# J7AEP_GPU_BXS464_WRAP0_GPU_SS_0_CORE_MMRS register map
Vendor: Texas Instruments
Registers are 64-bit, access per field, reset 0x0 unless marked. A register's access mark holds for its fields unless they carry their own. Offsets are as the file gives them; [hi:lo] are bit positions; lines under a group give offsets from that group; {n}, {i} and the like mark numbered series; 'fields as' and 'values as' point back to an identical list.

## J7AEP_GPU_BXS464_WRAP0_GPU_SS_0_CORE_MMRS (part 2 of 4)
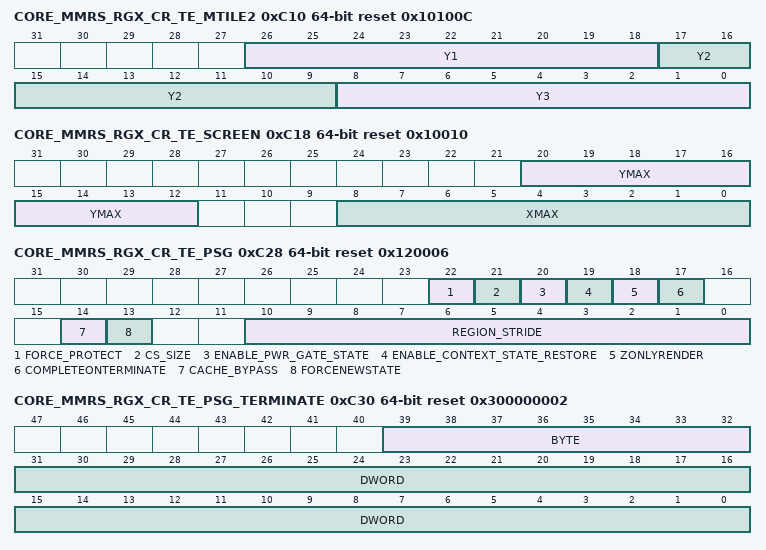
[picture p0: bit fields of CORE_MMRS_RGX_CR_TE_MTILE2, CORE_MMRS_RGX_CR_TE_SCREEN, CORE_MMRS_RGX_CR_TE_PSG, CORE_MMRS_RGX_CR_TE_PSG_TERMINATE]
0xC10 CORE_MMRS_RGX_CR_TE_MTILE2 reset 0x10100C
  [26:18] Y1 rw — X1 MacroTile boundary, ltop tile Y for second column of macrotiles [16MT mode] - 32 pixels tile height
  [17:9] Y2 rw — X2 MacroTile boundary, top tile Y for third[16MT] column of macrotiles - 32 pixels tile height
  [8:0] Y3 rw — X3 MacroTile boundary, top tile Y for fourth column of macrotiles [16MT] - 32 pixels tile height
0xC18 CORE_MMRS_RGX_CR_TE_SCREEN reset 0x10010
  [20:12] YMAX rw — Maximum Y tile address visible on screen, 32 pixel tile height, 16Kx16K max screen size
  [8:0] XMAX rw — Maximum X tile address visible on screen, 32 pixel tile width, 16Kx16K max screen size
0xC20 CORE_MMRS_RGX_CR_TE_MTILE
  [18:0] STRIDE rw — Number of tiles in a Macrotile. Stride = [XTile * YTiles], tiles 32 pixels across by 32 pixels
0xC28 CORE_MMRS_RGX_CR_TE_PSG reset 0x120006
  [22] FORCE_PROTECT rw — When set, the TE shall force the PROTECT bit to 1 for all tiles
  [21] CS_SIZE rw — Size of control stream chunk. 0x0 512 bit 0x1 1024 bit
  [20] ENABLE_PWR_GATE_STATE rw — Enables TE PSG power gate state init. 0x0 Disable 0x1 Enable
  [19] ENABLE_CONTEXT_STATE_RESTORE rw — Enables sampling of Driver TE_STATE_ISP_STATE_ID and TE_ACTIVE_MTILE registers on context switch/restore when set, when reset current local value is preserved.
  [18] ZONLYRENDER rw — Don't invalidate Tail Pointer Cache entries on a Terminate command. Only effective when COMPLETEONTERMINATE is 0x0 0x0 Do Invalidate 0x1 Don't Invalidate
  [17] COMPLETEONTERMINATE rw — 0x1 Write region headers, terminate streams and invalidate tail pointer cache entries on terminate. 0x0 If ZONLYRENDER = 0x0 then force an Interrupt, however if ZONLYRENDER = 0x1 then write region headers and terminate streams.
  [14] CACHE_BYPASS rw — when set, PSG sets its write only cache to bypass mode, effectively disabling the cache
  [13] FORCENEWSTATE rw — Always embed state information in control stream. Debug only.
  [10:0] REGION_STRIDE rw — Number of 4kB Pages devoted to region headers for each Render Target - max needed = 0x500
0xC30 CORE_MMRS_RGX_CR_TE_PSG_TERMINATE reset 0x300000002
  [39:32] BYTE rw — Byte to terminate all tile control streams with.
  [31:0] DWORD rw — Double-word to terminate all tile control streams with.
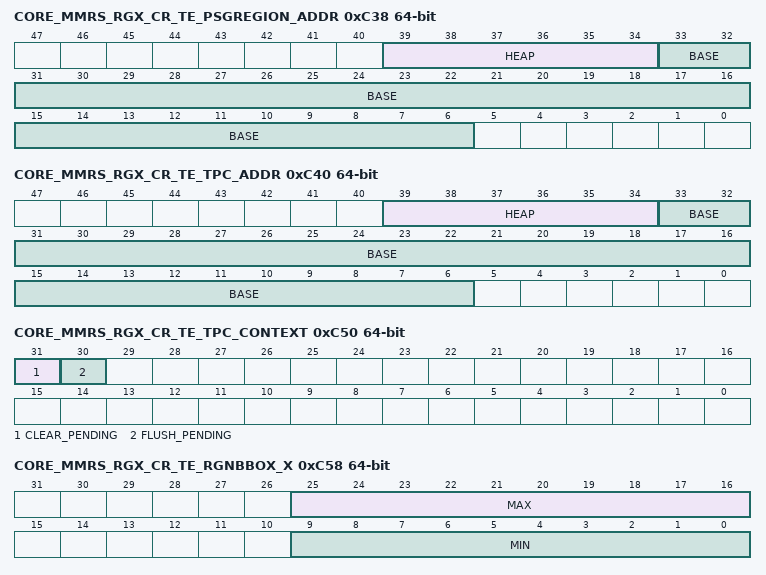
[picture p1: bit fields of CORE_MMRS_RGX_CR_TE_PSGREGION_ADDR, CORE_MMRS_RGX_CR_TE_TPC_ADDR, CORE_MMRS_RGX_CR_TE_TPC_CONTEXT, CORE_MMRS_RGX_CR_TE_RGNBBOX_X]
0xC38 CORE_MMRS_RGX_CR_TE_PSGREGION_ADDR
  [39:34] HEAP rw — 1TB Addressable, 16GB aligned Heap Address for Region Header writes
  [33:6] BASE rw — 16GB Addressable, 512-bit aligned Base Address for Region Header writes
0xC40 CORE_MMRS_RGX_CR_TE_TPC_ADDR
  [39:34] HEAP rw — 1TB Addressable, 16GB aligned Heap Address for Tail Pointer Cache.
  [33:6] BASE rw — 16GB Addressable, 512-bit aligned Base Address for Tail Pointer Cache entries. The tail pointer is the current last address written to for a control stream for a tile.
0xC48 CORE_MMRS_RGX_CR_TE_TPC reset 0x8
  [11:0] STRIDE rw — Number of 4KB pages per Render Target in each TPC footprint - max = 2048
0xC50 CORE_MMRS_RGX_CR_TE_TPC_CONTEXT
  [31] CLEAR_PENDING wo — Reset contents of Tail Pointer Cache
  [30] FLUSH_PENDING wo — Flush contents of Tail Pointer Cache to Memory
0xC58 CORE_MMRS_RGX_CR_TE_RGNBBOX_X ro
  [25:16] MAX — XMax value for maintained Region Generator Bounding Box, tiles 32 pixels in width
  [9:0] MIN — XMin value for maintained Region Generator Bounding Box, tiles 32 pixels in width
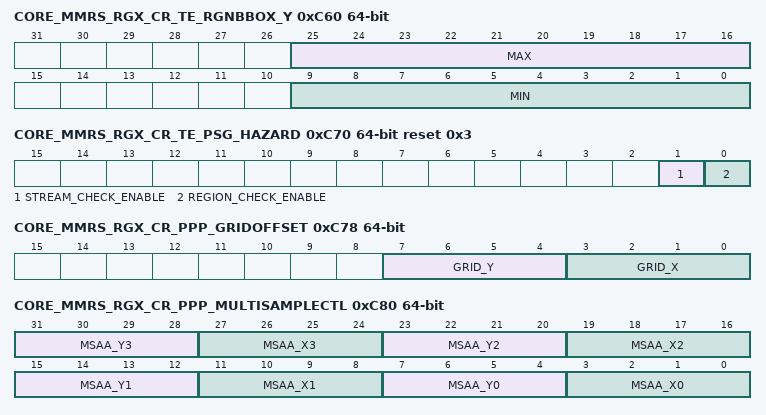
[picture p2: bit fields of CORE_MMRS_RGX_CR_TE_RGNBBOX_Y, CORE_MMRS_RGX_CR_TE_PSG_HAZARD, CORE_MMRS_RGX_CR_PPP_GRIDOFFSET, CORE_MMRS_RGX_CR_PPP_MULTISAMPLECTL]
0xC60 CORE_MMRS_RGX_CR_TE_RGNBBOX_Y ro
  [25:16] MAX — YMax value for maintained Region Generator Bounding Box, tiles 16 pixels in height
  [9:0] MIN — YMin value for maintained Region Generator Bounding Box, tiles 16 pixels in height
0xC68 CORE_MMRS_RGX_CR_TE_RGNHDR_INIT
  [0] PENDING wo — Start TE Region Header Initialisation
0xC70 CORE_MMRS_RGX_CR_TE_PSG_HAZARD reset 0x3
  [1] STREAM_CHECK_ENABLE rw — when set, PSG will enable hazard checking in the SLC for control stream writes
  [0] REGION_CHECK_ENABLE rw — when set, PSG will enable hazard checking in the SLC for region header writes
0xC78 CORE_MMRS_RGX_CR_PPP_GRIDOFFSET
  [7:4] GRID_Y rw — Unsigned sub-pixel offset
  [3:0] GRID_X rw — Unsigned sub-pixel offset
0xC80 CORE_MMRS_RGX_CR_PPP_MULTISAMPLECTL
  [31:28] MSAA_Y3 rw — Unsigned sub-pixel offset for the 4th multisample Y position
  [27:24] MSAA_X3 rw — Unsigned sub-pixel offset for the 4th multisample X position
  [23:20] MSAA_Y2 rw — Unsigned sub-pixel offset for the 3rd multisample Y position
  [19:16] MSAA_X2 rw — Unsigned sub-pixel offset for the 3rd multisample X position
  [15:12] MSAA_Y1 rw — Unsigned sub-pixel offset for the 2nd multisample Y position
  [11:8] MSAA_X1 rw — Unsigned sub-pixel offset for the 2nd multisample X position
  [7:4] MSAA_Y0 rw — Unsigned sub-pixel offset for the 1st multisample Y position
  [3:0] MSAA_X0 rw — Unsigned sub-pixel offset for the 1st multisample X position
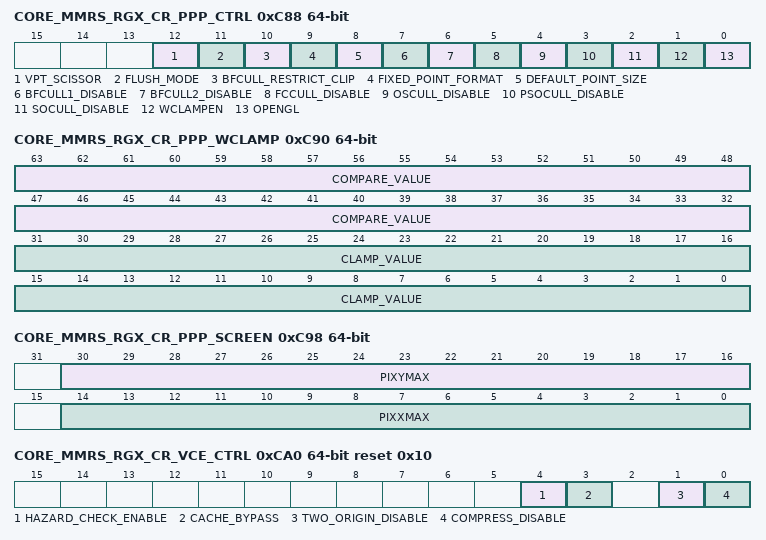
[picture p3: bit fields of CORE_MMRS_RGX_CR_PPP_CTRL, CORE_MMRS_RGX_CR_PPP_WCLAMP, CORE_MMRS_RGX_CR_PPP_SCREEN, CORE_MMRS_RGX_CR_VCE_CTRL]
0xC88 CORE_MMRS_RGX_CR_PPP_CTRL
  [12] VPT_SCISSOR rw — When 0 the PPP will insert state updates on change of VPT ID, When 1 this feature is disabled
  [11] FLUSH_MODE rw — when 0 PPP will supress end of draw call flushed from reaching the Clipper and TA pipeline, This will break batch number funstionality but will give better primitive block utiliastion. when 1 PPP will not supress any flushes
  [10] BFCULL_RESTRICT_CLIP rw — When set, clipped primitives are only back-face culled after the clipper. 0 Enable early back face cull for clipped primitives 1 Disable early cull
  [9] FIXED_POINT_FORMAT rw — When set, the PPP will use a fixed point format of 16. 8 rather than 16.4. 0 16.4 fixed point format 1 16.8 fixed point format
  [8] DEFAULT_POINT_SIZE rw — When set, the PPP will use the default point size rather than reading it from the vertex. 0 Point size read from vertex 1 Default point size of 3F800000 used
  [7] BFCULL1_DISABLE rw — Disable for fully clipped culling 0 First back face cull block enabled 1 First back face cull block disabled
  [6] BFCULL2_DISABLE rw — Disable for fully clipped culling 0 Second back face cull block enabled 1 Second back face cull block disabled
  [5] FCCULL_DISABLE rw — Disable for fully clipped culling 0 Fully clipped culling enabled 1 Fully clipped culling disabled
  [4] OSCULL_DISABLE rw — Disable for off screen culling 0 Off screen culling enabled 1 Off screen culling disabled
  [3] PSOCULL_DISABLE rw — Disable for perfect small object culling 0 Perfect small object culling enabled 1 Perfect small object culling disabled
  [2] SOCULL_DISABLE rw — Disable for small object culling 0 Small object culling enabled 1 Small object culling disabled
  [1] WCLAMPEN rw — Enable W clamping 0 W clamping disabled 1 W clamping enabled
  [0] OPENGL rw — Select OpenGL or D3D mode 0 D3D 1 OpenGL
0xC90 CORE_MMRS_RGX_CR_PPP_WCLAMP rw
  [63:32] COMPARE_VALUE — Compare value for W clamping. See the Input parameter format, viewport transform for details. Compare is applied post viewport transform. Note that this value cannot be negative.
  [31:0] CLAMP_VALUE — Clamp value for W clamping. See the Input parameter format, viewport transform for details. Clamp is applied post viewport transform, if the w value is less than the WCOMPARE value. Note that this value cannot be negative.
0xC98 CORE_MMRS_RGX_CR_PPP_SCREEN
  [30:16] PIXYMAX rw — Screen height in pixels. [16K x 16K max screen size]
  [14:0] PIXXMAX rw — Screen width in pixels.[16K x 16K max screen size]
0xCA0 CORE_MMRS_RGX_CR_VCE_CTRL reset 0x10
  [4] HAZARD_CHECK_ENABLE rw — when set, hazard checking will be enabled in SLC for parameter buffer writes
  [3] CACHE_BYPASS rw — when set, VCE sets its write only cache to bypass mode, effectively disabling the cache
  [1] TWO_ORIGIN_DISABLE rw — When set, raw mode is selected in place of 2-origin delta stream compression mode
  [0] COMPRESS_DISABLE rw — When set, vertex compression is disabled. I.e., raw mode is forced for all vertices
0xCA8 CORE_MMRS_RGX_CR_TE_CLEAR_LISTS_AFTER_ABORT
  [0] PULSE wo — TE Clears all references after Abort and Partial Render Sequence
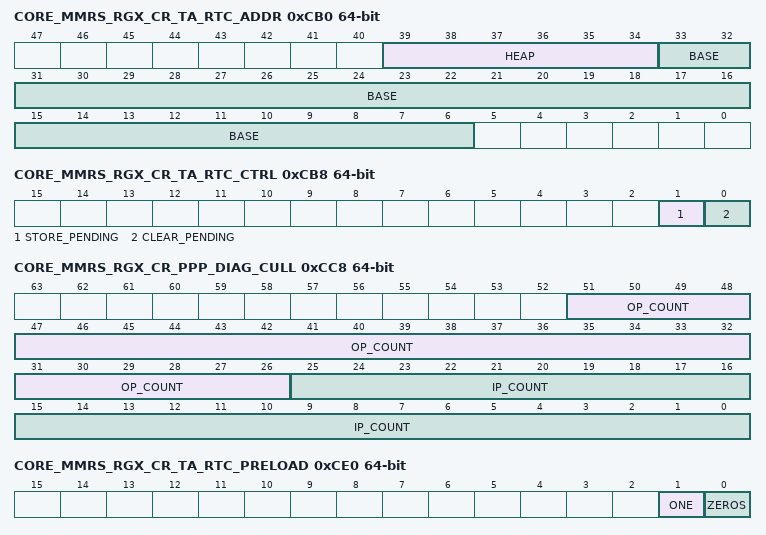
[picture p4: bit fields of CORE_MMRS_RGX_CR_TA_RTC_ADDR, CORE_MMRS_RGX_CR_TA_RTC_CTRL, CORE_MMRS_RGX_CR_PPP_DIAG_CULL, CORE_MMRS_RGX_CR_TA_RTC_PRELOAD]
0xCB0 CORE_MMRS_RGX_CR_TA_RTC_ADDR
  [39:34] HEAP rw — 1TB Addressable, 16GB aligned Heap Address for TA Render Target Caches
  [33:6] BASE rw — 16GB Addressabreadonly, le, 512-bit aligned Base Address for TA Render Target Caches.
0xCB8 CORE_MMRS_RGX_CR_TA_RTC_CTRL
  [1] STORE_PENDING wo — Store RTC
  [0] CLEAR_PENDING wo — Clear RTC
0xCC0 CORE_MMRS_RGX_CR_TA_CONTEXT_STATE_BASE
  [39:4] ADDR rw — 1TB range, 128-bit aligned base address
0xCC8 CORE_MMRS_RGX_CR_PPP_DIAG_CULL ro
  [51:26] OP_COUNT — count of primitives exiting the cull block
  [25:0] IP_COUNT — count of primitives entering the cull block
0xCD0 CORE_MMRS_RGX_CR_PPP ro
  [31:0] CHECKSUM — checksum generated from the output of the PPP
0xCD8 CORE_MMRS_RGX_CR_UVS_CLEAR
  [0] PENDING wo — Start UVS Clear Operation, a write to this register results in a one cycle pulse
0xCE0 CORE_MMRS_RGX_CR_TA_RTC_PRELOAD
  [1] ONE rw — Preload RTC with Render Target 0 set on a Clear. Used when resuming a TA phase after coarse grain context switch
  [0] ZEROS rw — Preload RTC with Zeros on a Clear
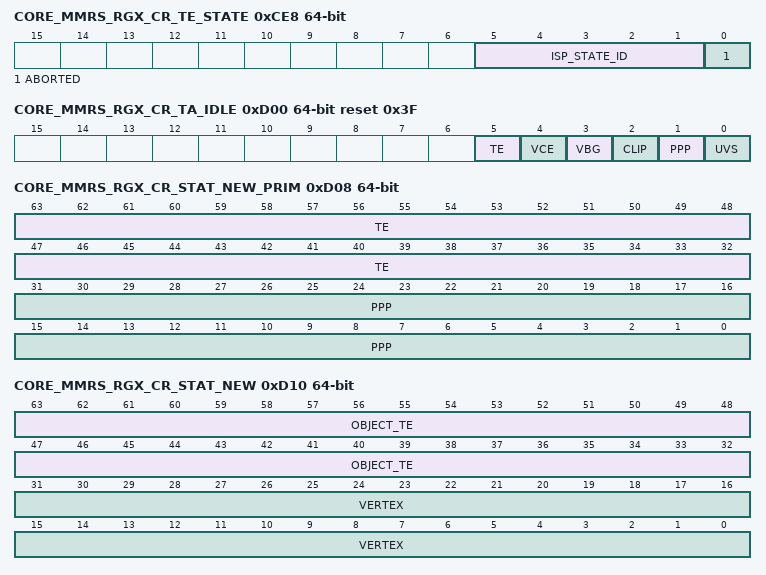
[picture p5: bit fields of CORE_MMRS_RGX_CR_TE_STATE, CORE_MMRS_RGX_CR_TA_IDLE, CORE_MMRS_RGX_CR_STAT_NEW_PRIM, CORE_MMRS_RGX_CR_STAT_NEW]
0xCE8 CORE_MMRS_RGX_CR_TE_STATE ro
  [5:1] ISP_STATE_ID
  [0] ABORTED — TA had been aborted in the past
0xCF0 CORE_MMRS_RGX_CR_VCE_HALT
  [0] PENDING wo — VCE is Halting after Current Block
0xCF8 CORE_MMRS_RGX_CR_TE_RESUME_AFTER_ABORT
  [0] PULSE wo — TE is restarted and reattempts failing allocation after Out Of Memory event only
0xD00 CORE_MMRS_RGX_CR_TA_IDLE ro reset 0x3F
  [5] TE — TE Module IDLE
  [4] VCE — VCE Module IDLE
  [3] VBG — VBG Module IDLE
  [2] CLIP — CLIP Module IDLE
  [1] PPP — PPP Module IDLE
  [0] UVS — UVS Module IDLE
0xD08 CORE_MMRS_RGX_CR_STAT_NEW_PRIM ro
  [63:32] TE — Number of primitives into TE
  [31:0] PPP — Number of primitives into PPP
0xD10 CORE_MMRS_RGX_CR_STAT_NEW ro
  [63:32] OBJECT_TE — Number of Control Stream Updates by TE
  [31:0] VERTEX — Number of vertices
0xD20 CORE_MMRS_RGX_CR_TE_PSG_RTC
  [11:0] ACTIVE_RTS rw — RTAs active at the point of the VDM Context SWitch
0xD28 CORE_MMRS_RGX_CR_VCE_CACHE_FLUSH
  [0] PENDING wo — VCE is Flushing its write only cache to memory
0xD30 CORE_MMRS_RGX_CR_TE_CACHE_FLUSH
  [0] PENDING wo — TE is Flushing its write only cache to memory
0xD38 CORE_MMRS_RGX_CR_PM_CACHE_FLUSH
  [0] PENDING wo — PM is Flushing its write only cache to memory
0xF00 CORE_MMRS_RGX_CR_ISP_START_RENDER
  [0] PULSE wo
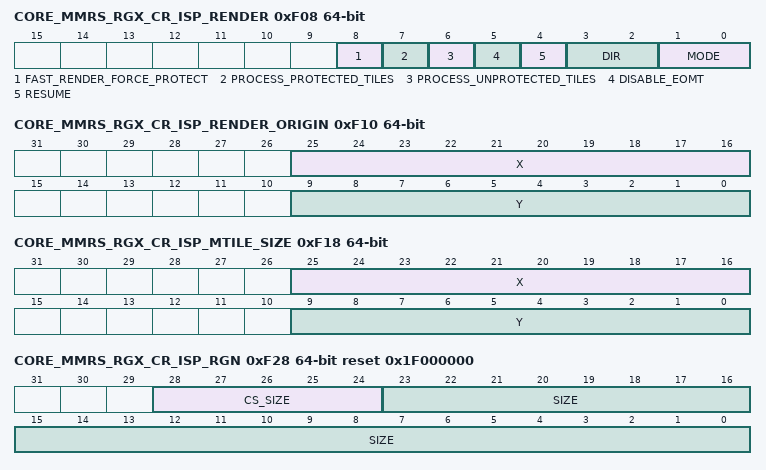
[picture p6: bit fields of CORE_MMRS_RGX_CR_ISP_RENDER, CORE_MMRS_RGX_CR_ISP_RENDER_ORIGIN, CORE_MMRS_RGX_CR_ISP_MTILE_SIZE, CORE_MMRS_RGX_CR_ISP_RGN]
0xF08 CORE_MMRS_RGX_CR_ISP_RENDER
  [8] FAST_RENDER_FORCE_PROTECT rw — When set, all tiles to be rasterised are marked as protected
  [7] PROCESS_PROTECTED_TILES rw — When set, protected tiles are processed
  [6] PROCESS_UNPROTECTED_TILES rw — When set, unprotected tiles are processed
  [5] DISABLE_EOMT rw — Prevent End-of-Macro-Tile flags being sent to ISP
  [4] RESUME rw — Render resume
  [3:2] DIR rw — Render direction
  [1:0] MODE rw — Render type
0xF10 CORE_MMRS_RGX_CR_ISP_RENDER_ORIGIN
  [25:16] X rw — X coordinate, in tiles
  [9:0] Y rw — Y coordinate, in tiles
0xF18 CORE_MMRS_RGX_CR_ISP_MTILE_SIZE
  [25:16] X rw — Macrotile width, in tiles. A value of zero corresponds to the maximum size
  [9:0] Y rw — Macrotile height, in tiles. A value of zero corresponds to the maximum size
0xF20 CORE_MMRS_RGX_CR_ISP_MTILE_BASE
  [39:2] ADDR rw — 1TB range, 32-bit aligned base address
0xF28 CORE_MMRS_RGX_CR_ISP_RGN reset 0x1F000000
  [28:24] CS_SIZE rw — Number of primitive headers in the control stream for a fast 2D render. If the number of primitive headers exceeds the maximum field size or the size of the control stream is unknown, a value of all ones should be written
  [23:0] SIZE rw — Number of Region Headers to fetch
0xF30 CORE_MMRS_RGX_CR_ISP_AA
  [1:0] MODE rw
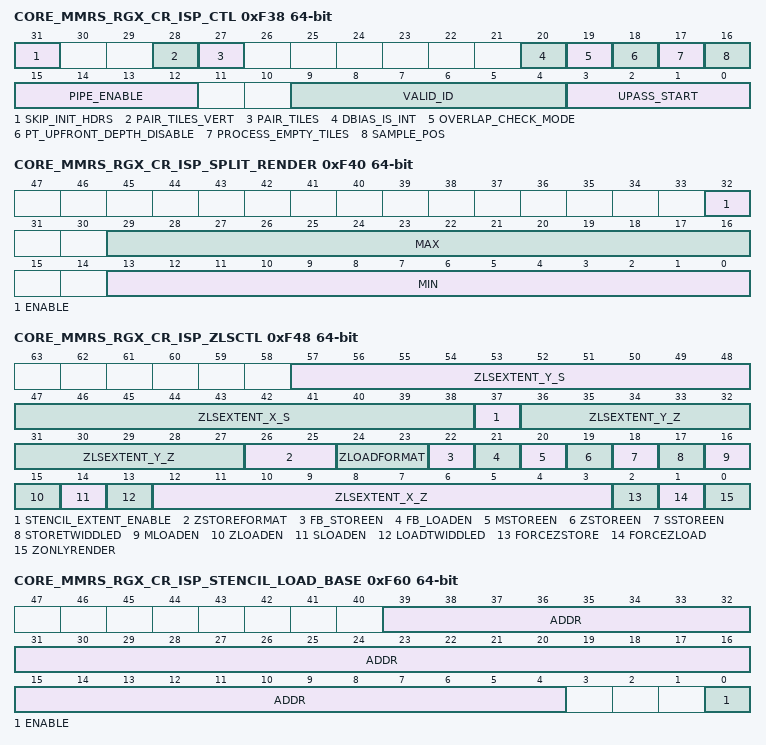
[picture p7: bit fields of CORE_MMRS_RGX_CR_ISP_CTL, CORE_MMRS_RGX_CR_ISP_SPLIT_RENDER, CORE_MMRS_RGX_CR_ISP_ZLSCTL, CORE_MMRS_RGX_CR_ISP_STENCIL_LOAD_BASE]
0xF38 CORE_MMRS_RGX_CR_ISP_CTL
  [31] SKIP_INIT_HDRS rw — Used to enable skipping of initial region headers based on gpu offset '0': reads all region headers and discards the ones not needed. '1': skip reading of region headers based on gpu offset
  [28] PAIR_TILES_VERT rw — If set, causes IPF to pair tiles vertically within its pipeline.
  [27] PAIR_TILES rw — If set, causes IPF to pair tiles within its pipeline.
  [20] DBIAS_IS_INT rw — When set, depth bias value is a signed integer
  [19] OVERLAP_CHECK_MODE rw — 0 - different samples for the same pixel will be sent to different pass groups for translucent objects [pixel to pixel overlap test] 1 - different samples for the same pixel will be sent as the same pass group [sample to sample overlap test]
  [18] PT_UPFRONT_DEPTH_DISABLE rw — When set, disable UPFRONT depth test in the Depthsorter
  [17] PROCESS_EMPTY_TILES rw — When set empty tiles are always processed rather than being suppressed
  [16] SAMPLE_POS rw — Specifies the sampling rule to be used when calculating the endpoint adjustment for thin lines
  [15:12] PIPE_ENABLE rw — Tiles-in-flight
  [9:4] VALID_ID rw — Triangle validation value
  [3:0] UPASS_START rw — User pass start value
0xF40 CORE_MMRS_RGX_CR_ISP_SPLIT_RENDER
  [32] ENABLE rw
  [29:16] MAX rw — Render up to and including this value
  [13:0] MIN rw — Render up from and including this value
0xF48 CORE_MMRS_RGX_CR_ISP_ZLSCTL
  [57:48] ZLSEXTENT_Y_S rw — For stencil buffer, the value calculation is the same as ZLSEXTENT_Y_Z
  [47:38] ZLSEXTENT_X_S rw — For stencil buffer, the value calculation is the same as ZLSEXTENT_X_Z
  [37] STENCIL_EXTENT_ENABLE rw — When this bit is '1', stencil buffer will use zlsextent_x/y_s value to calculate zload/store address, otherwise, zlsextent_x/y_z value will be used. The default value is '0' which disables this new function.
  [36:27] ZLSEXTENT_Y_Z rw — For Depth buffer Display width of Y in tiles minus one: 0x000 1 tile, 0x001 2 tiles, .. , 0x2FF 1024 tiles, zlsextent_y = total_samples_y / 32 samples in non-msaa, 4xmsaa mode = total_samples_y / 64 samples in 2xmsaa, 8xmsaa mode. In strided mode, zlsextent_y is set up to above result. In twiddled mode, zlsextent_y uses above result and rounds the value up to the nearest value which is power of 2.
  [26:25] ZSTOREFORMAT rw
  [24:23] ZLOADFORMAT rw
  [22] FB_STOREEN rw — when set, frame buffer compression store is enabled
  [21] FB_LOADEN rw — when set, frame buffer decompression load is enabled
  [20] MSTOREEN rw — When set and ZSTOREFORMAT = 0x0, mask plane is stored within msb of IEEE format, when set and ZSTOREFORMAT = 0x3, mask plane is stored at bit position 31 of IEEE format, when set for other format, if mask_store_base_enable = '1', background object mask data '0' is stored into separate memory address, when set for other format, if mask_store_base_enable = '0', mask data '0' is stored into separate meory address
  [19] ZSTOREEN rw — When set to 1, if the ZSTORE bit in the region header is also set then the depth buffer is stored to memory after each tile is processed
  [18] SSTOREEN rw — When set to 1, if the ZSTORE bit in the region header is also set then the stencil buffer is stored to memory after each tile is processed
  [17] STORETWIDDLED rw — When set to 1 depth and stencil data is written out in Twiddled order.
  [16] MLOADEN rw — When set and ZLOADFORMAT = 0x0, mask plane is loaded from msb of IEEE format, when set and ZLOADFORMAT = 0x3, mask plane is loaded from the bit position 31 of IEEE format, when set for other format, if mask_load_base_enable = '1', mask plane is loaded from separate memory address, when set for other format, if mask_load_base_enable = '0', background object mask data is used
  [15] ZLOADEN rw — When set to 1, if the ZLOAD bit in the region header is also set then the depth buffer is read from memory prior to tile processing
  [14] SLOADEN rw — When set to 1, if the ZLOAD bit in the region header is also set then the stencil buffer is read from memory prior to tile processing
  [13] LOADTWIDDLED rw — When set to 1 depth, stencil data is loaded in Twiddled order
  [12:3] ZLSEXTENT_X_Z rw — For depth buffer, Display width of X in tiles minus one: 0x000 1 tile, 0x001 2 tiles, .. , 0x2FF 1024 tiles. For different msaa mode, 1xmsaa = 1 x [32,32] pixels = 32x1 x 32x1 = 1024 samples = 32 x 32 samples, 2xmsaa = 2 x [32,32] pixels = 32x1 x 32x2 = 2048 samples = 32 x 64 samples, 4xmsaa = 4 x [32,16] pixels = 32x2 x 16x2 = 2048 samples = 64 x 32 samples, 8xmsaa = 8 x [16,16] pixels = 16x2 x 16x4 = 2048 samples = 32 x 64 samples, So zlsextent_x = total_samples_x / 32 samples when non-msaa, 2xmsaa, 8xmsaa zlsextent_x = total_samples_x / 64 samples when 4xmsaa In strided mode, zlsextent_x is set up to above result. In twiddled mode, zlsextent_x uses above result and rounds the value up to the neareast value which is power of 2.
  [2] FORCEZSTORE rw — If set to 1 the depth/stencil buffer is always stored at the end of each tile irrespective of the region header ZSTORE bit.
  [1] FORCEZLOAD rw — If set to 1 the depth/stencil buffer is always loaded at the start of each tile irrespective of the region header ZLOAD bit.
  [0] ZONLYRENDER rw — When set, only the Z buffer is rendered. Opaque and translucent objects are stencil and depth tested as usual but no pixel spans are emitted to the PDS Pixel presenter. Pixels within punch through and depth feedback objects are emitted on their first pass as a result of passing the up-front depth test by default. However, on their feedback depth test, these pixels will not be output regardless of the depth test result. The intention is to calculate a scene Z buffer without doing any further rendering.
0xF50 CORE_MMRS_RGX_CR_ISP_ZLOAD_BASE
  [39:4] ADDR rw — 1TB Addressable, 16byte aligned Base Address of the Z Buffer Load base address
0xF58 CORE_MMRS_RGX_CR_ISP_ZSTORE_BASE
  [39:4] ADDR rw — 1TB Addressable, 16byte aligned Base Address of the Z Buffer Store base address
0xF60 CORE_MMRS_RGX_CR_ISP_STENCIL_LOAD_BASE
  [39:4] ADDR rw — 1TB Addressable, 16byte aligned Base Address of the Z Buffer Load base address
  [0] ENABLE rw — When set to 1, enables fetching of stencil from a separate base address
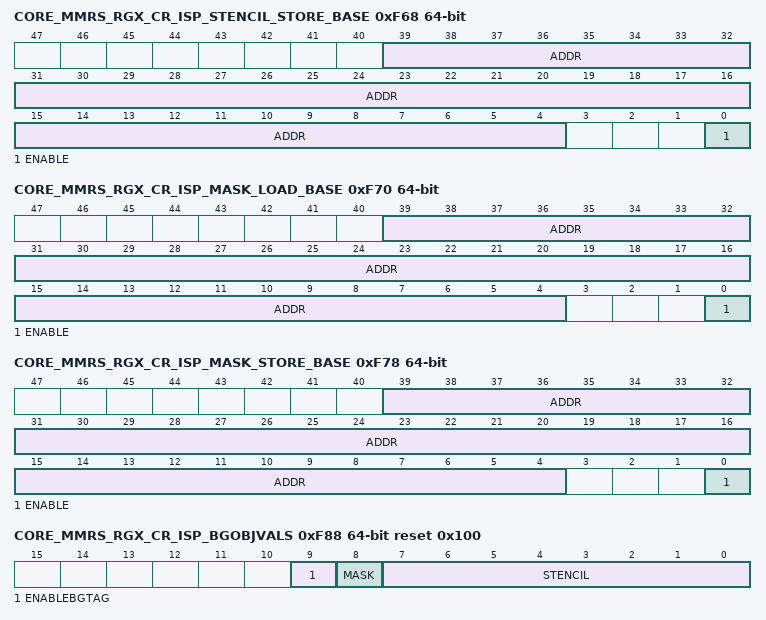
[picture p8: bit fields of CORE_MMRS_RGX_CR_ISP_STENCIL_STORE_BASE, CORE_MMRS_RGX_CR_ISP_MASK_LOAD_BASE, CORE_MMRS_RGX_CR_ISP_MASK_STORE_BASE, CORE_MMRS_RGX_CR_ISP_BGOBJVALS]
0xF68 CORE_MMRS_RGX_CR_ISP_STENCIL_STORE_BASE
  fields as CORE_MMRS_RGX_CR_ISP_STENCIL_LOAD_BASE
0xF70 CORE_MMRS_RGX_CR_ISP_MASK_LOAD_BASE
  [39:4] ADDR rw — 1TB Addressable, 16byte aligned Base Address of the Z Buffer Load base address
  [0] ENABLE rw — When set to 1, enables fetching of mask from a separate base address
0xF78 CORE_MMRS_RGX_CR_ISP_MASK_STORE_BASE
  fields as CORE_MMRS_RGX_CR_ISP_MASK_LOAD_BASE
0xF80 CORE_MMRS_RGX_CR_ISP_BGOBJDEPTH
  [31:0] VALUE rw — Note, the format in this register has to be consistent with the format defined by ZLS_STORE_FORMAT register. If depth buffer is F32, then the value here should be IEEE 754 single precisoin floating point If depth buffer is /INT16,then the value here should be UNORM24/UNORM16 foramt as well. Out of Range value will cause un-defined behavior.
0xF88 CORE_MMRS_RGX_CR_ISP_BGOBJVALS reset 0x100
  [9] ENABLEBGTAG rw — When set to 1, at the start of each tile the ISP tag buffer is initialised with the background object tag [default = 1]
  [8] MASK rw — Hardware background object mask plane
  [7:0] STENCIL rw — Hardware background object stencil
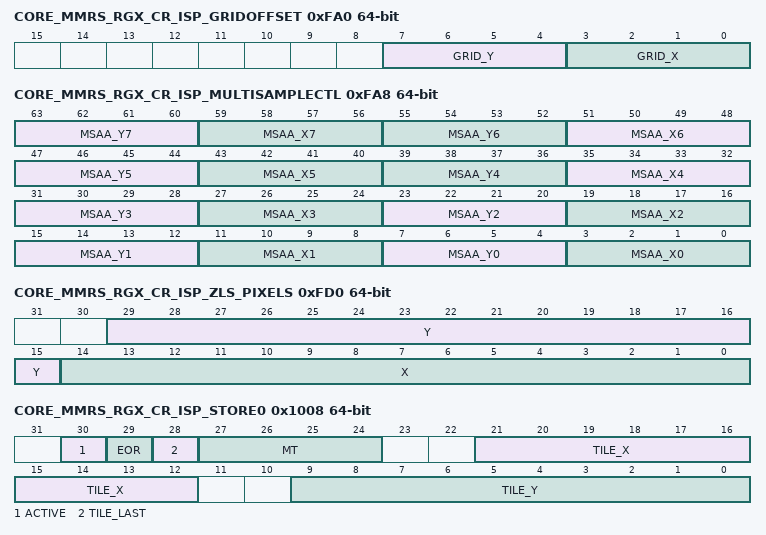
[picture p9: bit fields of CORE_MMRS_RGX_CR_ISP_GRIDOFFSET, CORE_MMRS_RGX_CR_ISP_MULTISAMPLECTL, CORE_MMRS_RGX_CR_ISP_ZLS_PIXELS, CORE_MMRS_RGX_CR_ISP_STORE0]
0xFA0 CORE_MMRS_RGX_CR_ISP_GRIDOFFSET
  fields as CORE_MMRS_RGX_CR_PPP_GRIDOFFSET
0xFA8 CORE_MMRS_RGX_CR_ISP_MULTISAMPLECTL rw
  [8n+7:8n+4] MSAA_Y{n} (n=3..7) — Unsigned sub-pixel offset for the {n+1}th multisample Y position
  [8n+3:8n] MSAA_X{n} (n=3..7) — Unsigned sub-pixel offset for the {n+1}th multisample X position
  [23:20] MSAA_Y2 — Unsigned sub-pixel offset for the 3rd multisample Y position
  [19:16] MSAA_X2 — Unsigned sub-pixel offset for the 3rd multisample X position
  [15:12] MSAA_Y1 — Unsigned sub-pixel offset for the 2nd multisample Y position
  [11:8] MSAA_X1 — Unsigned sub-pixel offset for the 2nd multisample X position
  [7:4] MSAA_Y0 — Unsigned sub-pixel offset for the 1st multisample Y position
  [3:0] MSAA_X0 — Unsigned sub-pixel offset for the 1st multisample X position
0xFB0 CORE_MMRS_RGX_CR_ISP_SCISSOR_BASE
  [39:2] ADDR rw — 1TB range, 32-bit aligned base address
0xFB8 CORE_MMRS_RGX_CR_ISP_DBIAS_BASE
  [39:2] ADDR rw — 1TB range, 32-bit aligned base address
0xFC0 CORE_MMRS_RGX_CR_ISP_OCLQRY_BASE
  [39:4] ADDR rw — 1TB range, 128-bit aligned base address
0xFC8 CORE_MMRS_RGX_CR_ISP_PIXEL_BASE
  [39:34] ADDR rw — 1TB range, 16GB granularity
0xFD0 CORE_MMRS_RGX_CR_ISP_ZLS_PIXELS
  [29:15] Y rw — Display width of Y in pixels minus one. 0x000 1 pixel, 0x001 2 pixels, ..., 0x7FFF 1024*32 pixels. Subtile only supports for non-msaa mode depth load/store, so For non-msaa mode, if framebuffer compression, or separate mask or separate stencil is enabled, [4 .. 0] has to be set to x1F. For 2xmsaa mode, [4 .. 0] has to be set to x1F. For 4xmsaa mode, [3 .. 0] has to be set to xF. For 8xmsaa mode, [3 .. 0] has to be set to xF.
  [14:0] X rw — Display width of X in pixels minus one. 0x000 1 pixel, 0x001 2 pixels, ..., 0x7FFF 1024*32 pixels. Subtile only supports for non-msaa mode depth load/store, so For non-msaa mode, if framebuffer compression, or separate mask or separate stencil is enabled, [4 .. 0] has to be set to x1F. For 2xmsaa mode, [4 .. 0] has to be set to x1F. For 4xmsaa mode, [4 .. 0] has to be set to x1F. For 8xmsaa mode, [3 .. 0] has to be set to xF.
0xFD8 CORE_MMRS_RGX_CR_ISP_CTL2 reset 0x10
  [4:0] DEPTHBUFFERS_IN_USE rw — Specifies the number of depth buffers to use
0x1000 CORE_MMRS_RGX_CR_ISP_START_CONTEXT_STORE
  [0] PULSE wo
0x1008 CORE_MMRS_RGX_CR_ISP_STORE0 ro
  [30] ACTIVE, [29] EOR, [28] TILE_LAST, [27:24] MT, [21:12] TILE_X, [9:0] TILE_Y
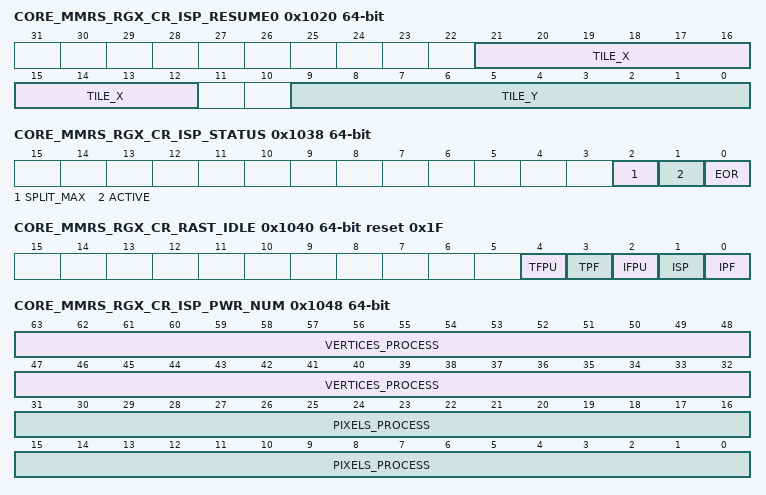
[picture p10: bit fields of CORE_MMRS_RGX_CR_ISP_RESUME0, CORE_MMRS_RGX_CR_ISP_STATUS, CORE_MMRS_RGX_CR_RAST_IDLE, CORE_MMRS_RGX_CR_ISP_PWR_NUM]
0x1020 CORE_MMRS_RGX_CR_ISP_RESUME0
  [21:12] TILE_X rw, [9:0] TILE_Y rw
0x1038 CORE_MMRS_RGX_CR_ISP_STATUS ro
  [2] SPLIT_MAX — Split Render Maximum Threshold has been Exceeded
  [1] ACTIVE — ISP is Active, first tile in the render has been assigned
  [0] EOR — ISP has assigned the last tile in the render
0x1040 CORE_MMRS_RGX_CR_RAST_IDLE ro reset 0x1F
  [4] TFPU — TFPU Module IDLE
  [3] TPF — TPF Module IDLE
  [2] IFPU — IFPU Module IDLE
  [1] ISP — ISP Module IDLE
  [0] IPF — IPF Module IDLE
0x1048 CORE_MMRS_RGX_CR_ISP_PWR_NUM ro
  [63:32] VERTICES_PROCESS — Number of vertices processed
  [31:0] PIXELS_PROCESS — Number of depth tested pixels[non-MSAA] or samples[MSAA] processed
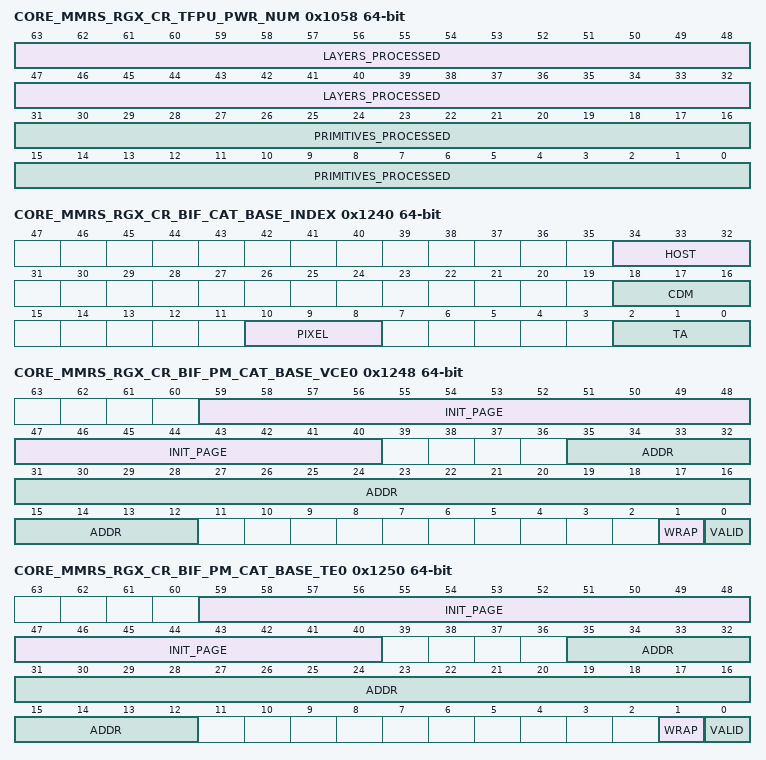
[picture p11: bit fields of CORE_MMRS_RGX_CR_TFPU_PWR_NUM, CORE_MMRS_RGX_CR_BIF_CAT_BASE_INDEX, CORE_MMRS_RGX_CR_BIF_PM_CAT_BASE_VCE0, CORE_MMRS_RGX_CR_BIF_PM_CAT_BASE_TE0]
0x1058 CORE_MMRS_RGX_CR_TFPU_PWR_NUM ro
  [63:32] LAYERS_PROCESSED — Number of layers processed
  [31:0] PRIMITIVES_PROCESSED — Number of primitives processed
0x11D0 CORE_MMRS_RGX_CR_ISP_MERGE_LOWER_X reset 0x378930A3
  [31:0] VALUE rw — tan[15]/16k screen size
0x11D8 CORE_MMRS_RGX_CR_ISP_MERGE_LOWER_Y reset 0x378930A3
  [31:0] VALUE rw — tan[15]/16k screen size
0x11E0 CORE_MMRS_RGX_CR_ISP_MERGE_UPPER_X reset 0x38DDB3D7
  [31:0] VALUE rw — tan[60]/16k screen size
0x11E8 CORE_MMRS_RGX_CR_ISP_MERGE_UPPER_Y reset 0x38DDB3D7
  [31:0] VALUE rw — tan[60]/16k screen size
0x11F0 CORE_MMRS_RGX_CR_ISP_MERGE_SCALE_X reset 0x48800000
  [31:0] VALUE rw — 16 * default screen size of 16k
0x11F8 CORE_MMRS_RGX_CR_ISP_MERGE_SCALE_Y reset 0x48800000
  [31:0] VALUE rw — 16 * default screen size of 16k
{0x1200+8i} CORE_MMRS_RGX_CR_BIF_CAT_BASE{i} (i=0..7)
  [39:12] ADDR rw
0x1240 CORE_MMRS_RGX_CR_BIF_CAT_BASE_INDEX
  [34:32] HOST rw — Catalogue Base number for HOST data master
  [18:16] CDM rw — Catalogue Base number for CDM data master
  [10:8] PIXEL rw — Catalogue Base number for PIXEL data master
  [2:0] TA rw — Catalogue Base number for TA data master
0x1248 CORE_MMRS_RGX_CR_BIF_PM_CAT_BASE_VCE0
  [59:40] INIT_PAGE rw
  [35:12] ADDR rw
  [1] WRAP rw — Indicates address space has been fully allocated
  [0] VALID rw
0x1250 CORE_MMRS_RGX_CR_BIF_PM_CAT_BASE_TE0
  [59:40] INIT_PAGE rw, [35:12] ADDR rw, [1] WRAP rw, [0] VALID rw
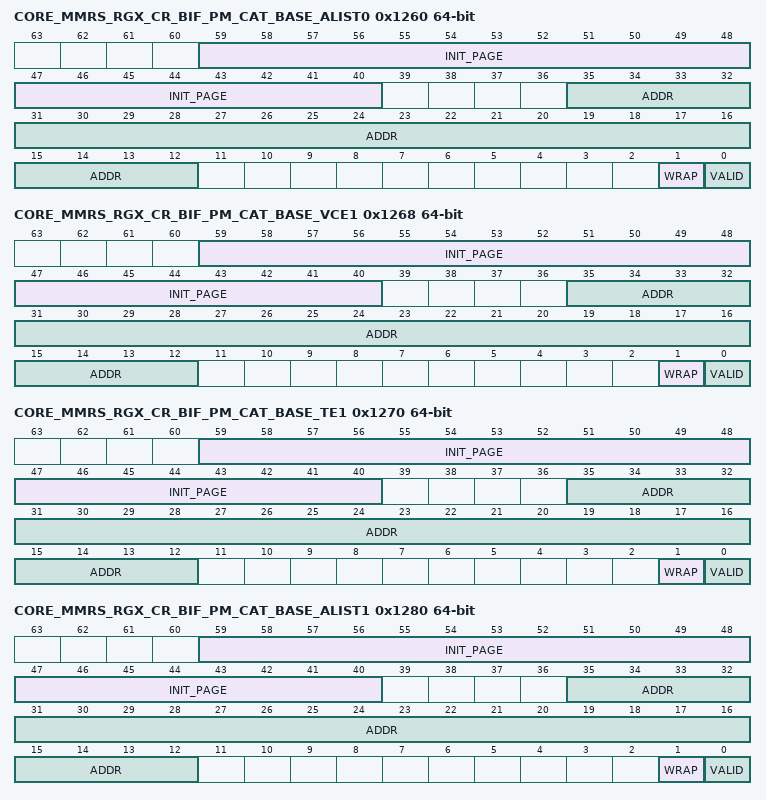
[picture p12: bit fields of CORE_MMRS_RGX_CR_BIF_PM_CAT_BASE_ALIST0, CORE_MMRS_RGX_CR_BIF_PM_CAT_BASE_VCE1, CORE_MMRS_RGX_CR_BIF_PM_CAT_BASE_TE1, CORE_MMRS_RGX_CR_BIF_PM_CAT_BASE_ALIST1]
0x1260 CORE_MMRS_RGX_CR_BIF_PM_CAT_BASE_ALIST0
  [59:40] INIT_PAGE rw, [35:12] ADDR rw, [1] WRAP rw, [0] VALID rw
0x1268 CORE_MMRS_RGX_CR_BIF_PM_CAT_BASE_VCE1
  [59:40] INIT_PAGE rw, [35:12] ADDR rw, [1] WRAP rw, [0] VALID rw
0x1270 CORE_MMRS_RGX_CR_BIF_PM_CAT_BASE_TE1
  [59:40] INIT_PAGE rw, [35:12] ADDR rw, [1] WRAP rw, [0] VALID rw
0x1280 CORE_MMRS_RGX_CR_BIF_PM_CAT_BASE_ALIST1
  [59:40] INIT_PAGE rw, [35:12] ADDR rw, [1] WRAP rw, [0] VALID rw
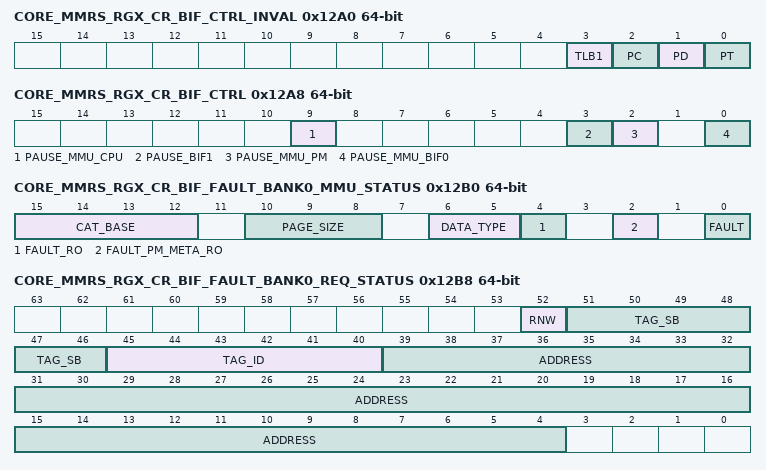
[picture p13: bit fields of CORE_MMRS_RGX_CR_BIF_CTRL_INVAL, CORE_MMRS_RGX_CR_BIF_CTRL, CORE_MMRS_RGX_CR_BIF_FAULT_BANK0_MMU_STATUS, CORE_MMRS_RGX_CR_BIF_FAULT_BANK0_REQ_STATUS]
0x12A0 CORE_MMRS_RGX_CR_BIF_CTRL_INVAL
  [3] TLB1 wo, [2] PC wo, [1] PD wo, [0] PT wo
0x12A8 CORE_MMRS_RGX_CR_BIF_CTRL
  [9] PAUSE_MMU_CPU rw — Stalls input to CPU MMU
  [3] PAUSE_BIF1 rw — Stalls BIF1 pipeline
  [2] PAUSE_MMU_PM rw — Stalls PM input to MMU
  [0] PAUSE_MMU_BIF0 rw — Stalls BIF0 input to MMU
0x12B0 CORE_MMRS_RGX_CR_BIF_FAULT_BANK0_MMU_STATUS ro
  [15:12] CAT_BASE — Catalogue base address number
  [10:8] PAGE_SIZE
  [6:5] DATA_TYPE — MMU data type that was invalid [on valid fault]
  [4] FAULT_RO — Indicates read-only fault['1'] or valid fault['0']
  [2] FAULT_PM_META_RO — Indicates pm/meta protected region fault
  [0] FAULT — Indicates a fault has occured
0x12B8 CORE_MMRS_RGX_CR_BIF_FAULT_BANK0_REQ_STATUS ro
  [52] RNW, [51:46] TAG_SB, [45:40] TAG_ID, [39:4] ADDRESS
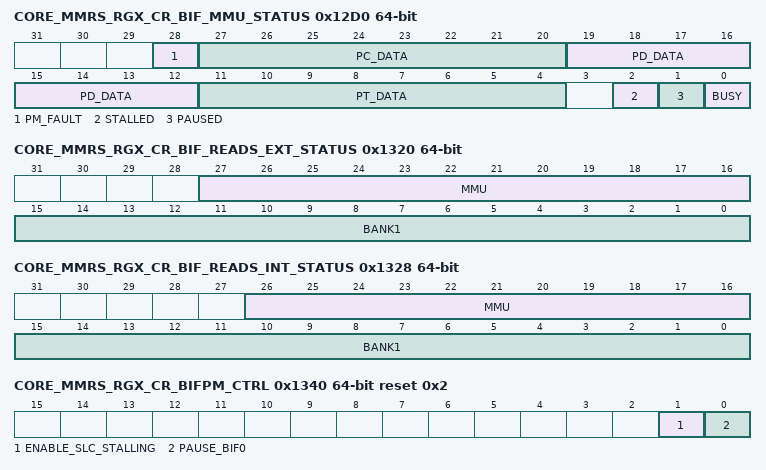
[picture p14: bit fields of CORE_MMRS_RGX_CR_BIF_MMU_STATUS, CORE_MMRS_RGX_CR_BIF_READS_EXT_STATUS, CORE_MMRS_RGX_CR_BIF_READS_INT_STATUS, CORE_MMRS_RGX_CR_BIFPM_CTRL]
0x12D0 CORE_MMRS_RGX_CR_BIF_MMU_STATUS ro
  [28] PM_FAULT, [27:20] PC_DATA, [19:12] PD_DATA, [11:4] PT_DATA, [2] STALLED, [1] PAUSED, [0] BUSY
0x1320 CORE_MMRS_RGX_CR_BIF_READS_EXT_STATUS ro
  [27:16] MMU, [15:0] BANK1
0x1328 CORE_MMRS_RGX_CR_BIF_READS_INT_STATUS ro
  [26:16] MMU, [15:0] BANK1
0x1330 CORE_MMRS_RGX_CR_BIFPM_READS_INT_STATUS ro
  [15:0] BANK0
0x1338 CORE_MMRS_RGX_CR_BIFPM_READS_EXT_STATUS ro
  [15:0] BANK0
0x1340 CORE_MMRS_RGX_CR_BIFPM_CTRL reset 0x2
  [1] ENABLE_SLC_STALLING rw — Enables BIF to stall returns from SLC so that requests can be made even when there is no space in the BIF return buffer [only when no chance of lockup]
  [0] PAUSE_BIF0 rw — Stalls BIF0 pipeline
0x1348 CORE_MMRS_RGX_CR_BIFPM_CTRL_INVAL
  [0] TLB0 wo
0x1350 CORE_MMRS_RGX_CR_BIFPM_STATUS_MMU ro
  [7:0] REQUESTS
0x1358 CORE_MMRS_RGX_CR_BIF_STATUS_MMU ro
  [7:0] REQUESTS
0x1370 CORE_MMRS_RGX_CR_BIF_BLACKPEARL_PWR ro
  [31:0] NUM_256BIT_TRANS — Number of 256-bit transactions
0x1378 CORE_MMRS_RGX_CR_BIF_JONES_PWR ro
  [31:0] NUM_256BIT_TRANS — Number of 256-bit transactions
0x13E0 CORE_MMRS_RGX_CR_BIF_FAULT_READ
  [39:4] ADDRESS rw
0x13E8 CORE_MMRS_RGX_CR_BIF_PWR ro
  [31:0] NUM_256BIT_TRANS — Number of 256-bit transactions
0x13F8 CORE_MMRS_RGX_CR_BIF_MCU_RESERVED
  [4:0] SPACE wo — Granularity of 8 spaces, minimum legal value 0x1
0x1430 CORE_MMRS_RGX_CR_TEXAS_BIF_FAULT_BANK0_MMU_STATUS ro
  fields as CORE_MMRS_RGX_CR_BIF_FAULT_BANK0_MMU_STATUS
0x1438 CORE_MMRS_RGX_CR_TEXAS_BIF_FAULT_BANK0_REQ_STATUS ro
  [50] RNW, [49:44] TAG_SB, [43:40] TAG_ID, [39:4] ADDRESS
0x1440 CORE_MMRS_RGX_CR_TEXAS_BIFPM_READS_INT_STATUS ro
  [15:0] BANK0
0x1448 CORE_MMRS_RGX_CR_TEXAS_BIFPM_READS_EXT_STATUS ro
  [15:0] BANK0
0x1450 CORE_MMRS_RGX_CR_TEXAS_BIFPM_STATUS_MMU ro
  [7:0] REQUESTS
0x1460 CORE_MMRS_RGX_CR_BIF_OSID0
  [8n+2:8n] CBASE{n} rw (n=0..7) — OSID for CAT BASE {n}
0x1468 CORE_MMRS_RGX_CR_BIF_OSID1
  [10:8] PM_CTX1 rw — OSID for VCE1, TE1 and ALIST1
  [2:0] PM_CTX0 rw — OSID for VCE0, TE0 and ALIST0
0x1470 CORE_MMRS_RGX_CR_TFBC_ZLS_COMPRESSOR_CFI
  [0] PENDING rw — Write a one to this register to initiate a flush of the ZLS TFBC Compressor cache. This register can be read. If the value is one, the this indicates a flush operation is underway.
0x1478 CORE_MMRS_RGX_CR_TFBC_PBE_COMPRESSOR_CFI
  [0] PENDING rw — Write a one to this register to initiate a flush of the PBE TFBC Compressor cache. This register can be read. If the value is one, the this indicates a flush operation is underway.
0x1480 CORE_MMRS_RGX_CR_TFBC_ZLS_DECOMPRESSOR_CFI
  [0] INVALIDATE wo — Informs the ZLS decompressor to invalidate its cache.
0x1488 CORE_MMRS_RGX_CR_TFBC_TPU_DECOMPRESSOR_CFI
  [0] INVALIDATE wo — Informs the TPU decompressor to invalidate its cache.
0x1490 CORE_MMRS_RGX_CR_TFBC_CACHE_CTRL reset 0x4CD33
  [21] ZLS_DECOMPRESSOR_BYPASS rw — When set to 1, the ZLS decompressor cache is disabled.
  [20] TPU_DECOMPRESSOR_BYPASS rw — When set to 1, the TPU decompressor cache is disabled.
  [19] ZLS_COMPRESSOR_DELTA_NOHAZARD rw — When set to 1, the ZLS compressor no_hazard signal is set high to the SLC for delta writes. This will cause the TFBC to disable hazard checking in the SLC for delta writes.
  [18] ZLS_COMPRESSOR_HEADER_NOHAZARD rw — When set to 1, the ZLS compressor no_hazard signal is set high to the SLC for header writes. This will cause the TFBC to disable hazard checking in the SLC for header writes.
  [17] ZLS_COMPRESSOR_DELTA_NOLINEFILL rw — When set to 0, the ZLS compressor line fills data from memory before writing data back for deltas. When set to 1, the ZLS compressor does not line fill from memory for deltas.
  [16] ZLS_COMPRESSOR_HEADER_NOLINEFILL rw — When set to 0, the ZLS compressor line fills data from memory before writing data back for headers. When set to 1, the ZLS compressor does not line fill from memory for headers.
  [15] ZLS_COMPRESSOR_DELTA_POLICY_OVERRIDE rw — When set to 0, the ZLS compressor will use the SLC policy supplied by the ZLS for delta writes. When set to 1, the ZLS compressor will use the ZLS_COMPRESSOR_DELTA_POLICY for delta writes.
  [14] ZLS_COMPRESSOR_HEADER_POLICY_OVERRIDE rw — When set to 0, the ZLS compressor will use the SLC policy supplied by the ZLS for header writes. When set to 1, the ZLS compressor will use the ZLS_COMPRESSOR_HEADER_POLICY for header writes.
  [13:12] ZLS_COMPRESSOR_DELTA_POLICY rw — SLC cache policy applied to ZLS compressor delta writes when ZLS_COMPRESSOR_DELTA_POLICY_OVERRIDE is set to 1
  [11:10] ZLS_COMPRESSOR_HEADER_POLICY rw — SLC cache policy applied to ZLS compressor header writes when ZLS_COMPRESSOR_HEADER_POLICY_OVERRIDE is set to 1
  [9] PBE_COMPRESSOR_DELTA_NOHAZARD rw — When set to 1, the PBE compressor no_hazard signal is set high to the SLC for delta writes. This will cause the TFBC to disable hazard checking in the SLC for delta writes.
  [8] PBE_COMPRESSOR_HEADER_NOHAZARD rw — When set to 1, the PBE compressor no_hazard signal is set high to the SLC for header writes. This will cause the TFBC to disable hazard checking in the SLC for header writes.
  [7] PBE_COMPRESSOR_DELTA_NOLINEFILL rw — When set to 0, the PBE compressor line fills data from memory before writing data back for deltas. When set to 1, the PBE compressor does not line fill from memory for deltas.
  [6] PBE_COMPRESSOR_HEADER_NOLINEFILL rw — When set to 0, the PBE compressor line fills data from memory before writing data back for headers. When set to 1, the PBE compressor does not line fill from memory for headers.
  [5] PBE_COMPRESSOR_DELTA_POLICY_OVERRIDE rw — When set to 0, the PBE compressor will use the SLC policy supplied by the PBE for delta writes. When set to 1, the PBE compressor will use the PBE_COMPRESSOR_DELTA_POLICY for delta writes.
  [4] PBE_COMPRESSOR_HEADER_POLICY_OVERRIDE rw — When set to 0, the PBE compressor will use the SLC policy supplied by the PBE for header writes. When set to 1, the PBE compressor will use the PBE_COMPRESSOR_HEADER_POLICY for header writes.
  [3:2] PBE_COMPRESSOR_DELTA_POLICY rw — SLC cache policy applied to PBE compressor delta writes when PBE_COMPRESSOR_DELTA_POLICY_OVERRIDE is set to 1
  [1:0] PBE_COMPRESSOR_HEADER_POLICY rw — SLC cache policy applied to PBE compressor header writes when PBE_COMPRESSOR_HEADER_POLICY_OVERRIDE is set to 1
0x1498 CORE_MMRS_RGX_CR_TFBC_CTRL
  [1] ZLS_CRC_ENABLE rw — Enable the generation of CRCs for compression depth buffer writes.
  [0] PBE_CRC_ENABLE rw — Enable the generation of CRCs for compressed frame buffer writes.
0x1500 CORE_MMRS_RGX_CR_PBE
  [8] AA_EDGEOPT_OFF rw — Switches off the PBE-USE read optimisation during Anti aliasing mode. [This is typically for debug purposes only]
  [7:0] ALPHATHRESHOLD rw — Alpha threshold used when encoding 1555 format. If the internal 8bit Alpha value exceeds this value, then a 1 is written to the top bit of the output, otherwise a 0 is written
0x1508 CORE_MMRS_RGX_CR_PBE_EMIT_STATUS ro reset 0xFFFF
  [n] USC{n} (n=0..15) — Pipe {n} status
{0x1510+8i} CORE_MMRS_RGX_CR_PBE_WORD0_MRT{i} rw (i=0..7)
  [63:62] TFBC_LOSSY — Sets the lossy bit for frame buffer compression
  [61] COMPRESS_SIZE_EXT — Extra bit to support 32x2 compression size, used with COMPRESS_SIZE register bit to define 8x8; 16x4 or 32x2 size COMPRESS_SIZE_EXT COMPRESS_SIZE SIZE 0 0 8x8 0 1 16x4 1 0 32x2 1 1 reserved
  [60] PAIR_TILES — If set, then PBE will pair 16x16 tiles
  [59] X_RSRVD2 — Not used
  [58] DITHER — Enable dither
  [57] TILERELATIVE — Add tile offset
  [56] DOWNSCALE — Perform box filter downscale
  [55:52] SIZE_Z — Z Size in pixels [log 2]
  [51:50] ROTATION — Rotation angle
  [49:34] LINESTRIDE — Linestride in 2 pixel units. 0 == 2. Supports 32KDWORD stride memory write
  [33:32] MEMLAYOUT — Memory layout
  [3n+22:3n+20] SWIZ_CHAN{n} (n=0..3) — Swizzle for destination channel {n}
  [19:6] MINCLIP_X — Min X Clip
  [5] TWOCOMP_GAMMA — Sets the gamma mode for 2 component targets
  [4] GAMMA — Gamma enabled
  [3] COMPRESSION — Frame buffer Compression enabled
  [2] COMPRESS_SIZE — Block size for the compressor, used with COMPRESS_SIZE_EXT register bit to define 8x8; 16x4 or 32x2 size COMPRESS_SIZE_EXT COMPRESS_SIZE SIZE 0 0 8x8 0 1 16x4 1 0 32x2 1 1 reserved
  [1] COMP_INDIRECT_TABLE — If set indicates to the compressor that an indirect addressing is used otherwise direct addressing
  [0] Y_FLIP
{0x1550+8i} CORE_MMRS_RGX_CR_PBE_WORD1_MRT{i} rw (i=0..7)
  [63:60] SIZE_X — X Size in pixels [log 2]
  [59:46] MINCLIP_Y — Min Y Clip
  [45:32] MAXCLIP_X — Max X clip
  [31:28] SIZE_Y — Y Size in pixels [log 2]
  [27:14] ZSLICE — Slice number for render to 3D twiddle target
  [13:0] MAXCLIP_Y — Max Y clip
0x1590 CORE_MMRS_RGX_CR_PBE_PWR ro
  [31:0] NUM_PIXELS_PROCESSED — Number of on-edge/off-edge pixels per tile.
0x1720 CORE_MMRS_RGX_CR_MCU_GLB_CFI
  [5] FENCE wo — When set, additionally perform a fence to external memory before signalling that a flush is complete
  [4] DM_COMPUTE wo — When set, perform operation on compute data master
  [3] DM_PIXEL wo — When set, perform operation on pixel data master
  [2] DM_VERTEX wo — When set, perform operation on vertex data master
  [1] FLUSH wo — When set, will flush cache based on data master
  [0] INVALIDATE wo — When set, will invalidate cache based on data master. This bit will also invalidate the L0 cache in the MADD and teh YUV cache in the TAG to reset the CSC coefficients.
0x1728 CORE_MMRS_RGX_CR_MCU_GLB_CFI_EVENT ro
  [0] PENDING — 1 Indicate there is a pending global CFI operation on the MCU
0x1730 CORE_MMRS_RGX_CR_MCU_LIMIT
  [23:16] DM_COMPUTE rw — Maximum number of cachelines which can be used by the Compute data master
  [15:8] DM_PIXEL rw — Maximum number of cachelines which can be used by the Pixel data master
  [7:0] DM_VERTEX rw — Maximum number of cachelines which can be used by the Vertex data master
0x1738 CORE_MMRS_RGX_CR_MCU_CTRL reset 0xAB40
  [17] PDSRW_L0_OFF rw — Turn off MCU PDSRW L0 cache
  [16:9] FBDC_REQ_THRESHOLD rw — Maximum number of outstanding requests each MCU group can have to the Framebuffer Decompression module
  [8] RD_OVERTAKE_THRESH_ENABLE rw — Enables the use of the threshold to limit the amount of overtaking which is permitted
  [7:2] RD_OVERTAKE_THRESHOLD rw — The number of read accesses which are permitted to overtake waiting Writebacks when enabled
  [1] INSTANCE_MERGE_DISABLE rw — Turn off instance merging in the MCU L1
  [0] L1_OFF rw — Turn off MCU L1
0x1740 CORE_MMRS_RGX_CR_MCU_FENCE
  [42:40] DM rw — Data Master value to use when issuing a Fence
  [39:5] ADDR rw — Address value to use when issuing a Fence
